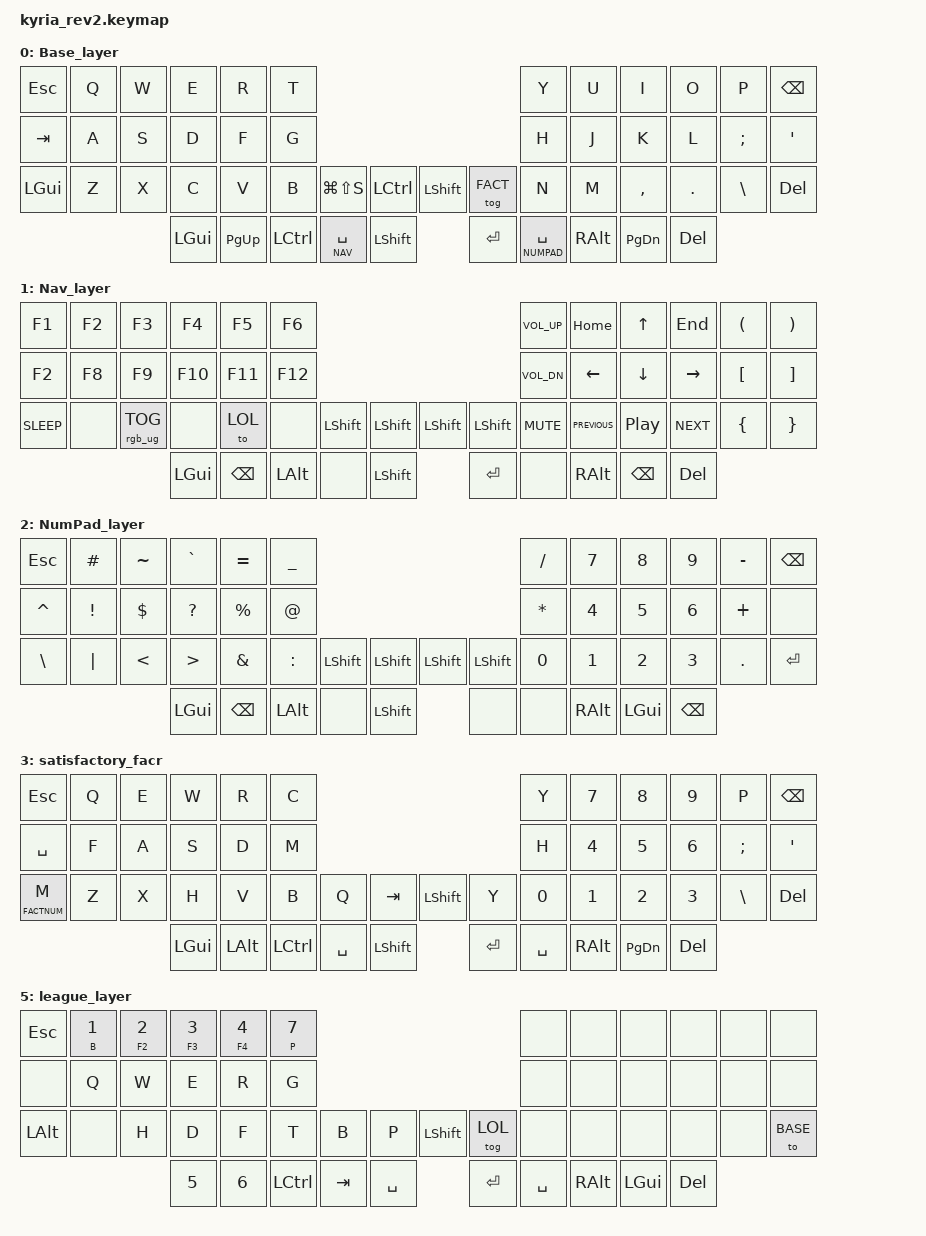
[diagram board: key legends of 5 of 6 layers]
#include <behaviors.dtsi>
#include <dt-bindings/zmk/keys.h>
#include <dt-bindings/zmk/bt.h>
#include <dt-bindings/zmk/rgb.h>

#define BASE 0
#define NAV 1
#define NUMPAD 2
#define FACT 3
#define FACTNUM 4
#define LOL 5

/ {
  behaviors {
        qtp: positional_hold_tap {
            compatible = "zmk,behavior-hold-tap";
            label = "league_quick_tap";
            #binding-cells = <2>;
            flavor = "tap-preferred";
            tapping-term-ms = <300>;
            quick-tap-ms = <200>;
            bindings = <&kp>, <&kp>;
        };
  };

  keymap {
    compatible = "zmk,keymap";

    Base_layer {
      bindings = <
        &kp ESC  &kp Q &kp W &kp E &kp R &kp T                                                          &kp Y &kp U &kp I &kp O &kp P &kp BACKSPACE 
        &kp TAB  &kp A &kp S &kp D &kp F &kp G                                                          &kp H &kp J &kp K &kp L &kp SEMICOLON &kp SINGLE_QUOTE 
        &kp LGUI &kp Z &kp X &kp C &kp V &kp B &kp LG(LS(S)) &kp LEFT_CONTROL     &kp LSHFT &tog FACT &kp N &kp M &kp COMMA &kp PERIOD &kp BACKSLASH &kp DEL 
            &kp LGUI &kp PG_UP &kp LEFT_CONTROL &lt NAV SPACE &kp LEFT_SHIFT    &kp RETURN &lt NUMPAD SPACE &kp RIGHT_ALT &kp PG_DN &kp DEL 
      >;
    };
    Nav_layer {
      bindings = <
        &kp F1  &kp F2 &kp F3 &kp F4  &kp F5  &kp F6                                     &kp C_VOL_UP   &kp HOME         &kp UP     &kp END    &kp LEFT_PARENTHESIS &kp RIGHT_PARENTHESIS 
        &kp F2  &kp F8 &kp F9 &kp F10 &kp F11 &kp F12                                    &kp C_VOL_DN   &kp LEFT         &kp DOWN   &kp RIGHT  &kp LEFT_BRACKET     &kp RIGHT_BRACKET  
        &kp C_SLEEP &none &rgb_ug RGB_TOG &none &to LOL &none &kp LSHFT &kp LSHFT        &kp LSHFT &kp LSHFT &kp C_MUTE     &kp C_PREVIOUS   &kp C_PLAY_PAUSE &kp C_NEXT &kp LEFT_BRACE &kp RIGHT_BRACE 
                  &kp LGUI &kp BACKSPACE &kp LEFT_ALT &none &kp LEFT_SHIFT               &kp RETURN &none &kp RIGHT_ALT &kp BACKSPACE &kp DEL  
      >;
    };

    NumPad_layer {
      bindings = <
        &kp ESCAPE    &kp HASH        &kp TILDE  &kp GRAVE    &kp EQUAL      &kp UNDERSCORE                                           &kp SLASH    &kp NUMBER_7 &kp NUMBER_8 &kp NUMBER_9 &kp MINUS  &kp BACKSPACE 
        &kp CARET     &kp EXCLAMATION &kp DOLLAR &kp QUESTION &kp PERCENT    &kp AT_SIGN                                              &kp ASTERISK &kp NUMBER_4 &kp NUMBER_5 &kp NUMBER_6 &kp PLUS   &none  
        &kp BACKSLASH &kp PIPE        &kp LT     &kp GT       &kp AMPERSAND  &kp COLON &kp LSHFT &kp LSHFT        &kp LSHFT &kp LSHFT &kp NUMBER_0 &kp NUMBER_1 &kp NUMBER_2 &kp NUMBER_3 &kp PERIOD &kp RETURN
                                                 &kp LGUI &kp BACKSPACE &kp LEFT_ALT  &none &kp LEFT_SHIFT              &none  &none  &kp RIGHT_ALT &kp LGUI &kp BACKSPACE
      >;
    };

    satisfactory_facr {
      bindings = <
        &kp ESC  &kp Q &kp E &kp W &kp R &kp C                                                          &kp Y &kp NUMBER_7 &kp NUMBER_8 &kp NUMBER_9 &kp P &kp BACKSPACE 
        &kp SPACE  &kp F &kp A &kp S &kp D &kp M                                                          &kp H &kp NUMBER_4 &kp NUMBER_5 &kp NUMBER_6 &kp SEMICOLON &kp SINGLE_QUOTE 
        &lt FACTNUM M  &kp Z &kp X &kp H &kp V &kp B &kp Q &kp TAB     &kp LSHFT &kp Y &kp NUMBER_0 &kp NUMBER_1 &kp NUMBER_2 &kp NUMBER_3 &kp BACKSLASH &kp DEL 
            &kp LGUI &kp LEFT_ALT &kp LEFT_CONTROL &kp SPACE &kp LEFT_SHIFT    &kp RETURN &kp SPACE &kp RIGHT_ALT &kp PG_DN &kp DEL 
      >;
    };

     satisfactory_num {
      bindings = <
        &kp ESC &kp NUMBER_7 &kp NUMBER_8 &kp NUMBER_9 &kp C                                                          &kp Y &kp NUMBER_7 &kp NUMBER_8 &kp NUMBER_9 &kp P &kp BACKSPACE 
        &kp SPACE  &kp A &kp NUMBER_4 &kp NUMBER_5 &kp NUMBER_6 &kp M                                                          &kp H &kp NUMBER_4 &kp NUMBER_5 &kp NUMBER_6 &kp SEMICOLON &kp SINGLE_QUOTE 
        &none &kp NUMBER_0 &kp NUMBER_1 &kp NUMBER_2 &kp NUMBER_3 &kp B &kp Q &kp TAB     &kp LSHFT &tog FACT &kp NUMBER_0 &kp NUMBER_1 &kp NUMBER_2 &kp NUMBER_3 &kp BACKSLASH &kp DEL 
            &kp LGUI &kp LEFT_ALT &kp LEFT_CONTROL &kp SPACE &kp LEFT_SHIFT    &kp RETURN &kp SPACE &kp RIGHT_ALT &kp PG_DN &kp DEL 
      >;
    };
  
    league_layer {
      bindings = <
        &kp ESC &qtp B N1 &qtp F2 N2 &qtp F3 N3 &qtp F4 N4 &qtp P N7                              &none &none &none &none &none &none
        &none &kp Q &kp W &kp E &kp R &kp G                                                       &none &none &none &none &none &none
        &kp LEFT_ALT &none &kp H &kp D &kp F &kp T &kp B &kp P                &kp LSHFT &tog LOL &none &none &none &none &none &to BASE
                       &kp N5 &kp N6 &kp LCTRL  &kp TAB &kp SPACE             &kp RETURN &kp SPACE &kp RIGHT_ALT &kp LGUI &kp DEL 
      >;
    };

    // template_layer {
    //   bindings = <
    //     &none &none &none &none &none &none         &none &none &none &none &none &none
    //     &none &none &none &none &none &none         &none &none &none &none &none &none
    //     &none &none &none &none &none &none         &none &none &none &none &none &none
    //     &kp LEFT_ALT  &kp LEFT_SHIFT &none          &none  &kp RETURN &kp RIGHT_ALT 
    //   >;
    // };
  };
};  
